# STM32F107VCT7 register map
File version: 1.0
Registers are 32-bit, access not given, reset 0x0 unless marked. A register's access mark holds for its fields unless they carry their own. Offsets are from the block's base; [hi:lo] are bit positions; {n}, {i} and the like mark numbered series.

## FLASH
Base 0x40022000
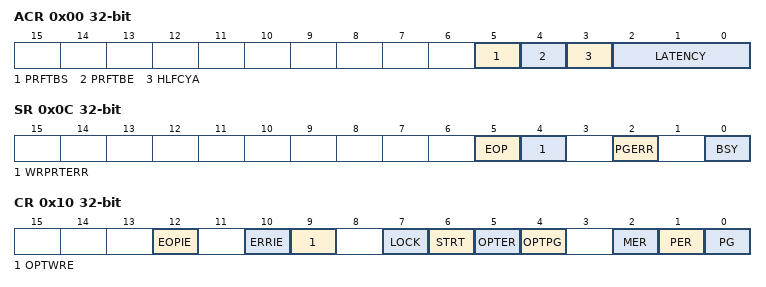
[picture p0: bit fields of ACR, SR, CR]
0x00 ACR
  [5] PRFTBS, [4] PRFTBE, [3] HLFCYA, [2:0] LATENCY
0x04 KEYR
  [31:0] FKEYR
0x08 OPTKEYR
0x0C SR
  [5] EOP, [4] WRPRTERR, [2] PGERR, [0] BSY
0x10 CR
  [12] EOPIE, [10] ERRIE, [9] OPTWRE, [7] LOCK, [6] STRT, [5] OPTER, [4] OPTPG, [2] MER, [1] PER, [0] PG
0x14 AR
  [31:0] FAR
0x1C OBR
  [25:18] DATA1, [17:10] DATA0, [4] nRST_STDBY, [3] nRST_STOP, [4:2] USER, [1] RDPRT, [0] OPTERR
0x20 WRPR
  [31:0] WRP

## CRC
Base 0x40023000
0x00 DR
0x04 IDR 8-bit
0x08 CR
  [0] RESET

## ETH
Base 0x40028000
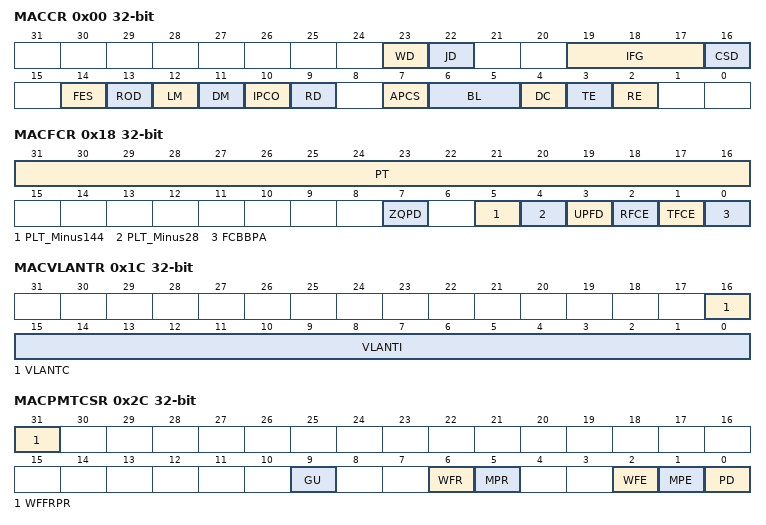
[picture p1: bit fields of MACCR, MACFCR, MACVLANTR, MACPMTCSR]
0x00 MACCR
  [23] WD, [22] JD, [19:17] IFG, [16] CSD, [14] FES, [13] ROD, [12] LM, [11] DM, [10] IPCO, [9] RD, [7] APCS, [6:5] BL, [4] DC, [3] TE, [2] RE
0x04 MACFFR
  [31] RA, [10] HPF, [9] SAF, [8] SAIF, [7] PCF_ForwardAll, [7:6] PCF_ForwardPassedAddrFilter, [5] BFD, [4] PAM, [3] DAIF, [2] HM, [1] HU, [0] PM
0x08 MACHTHR
  [31:0] HTH
0x0C MACHTLR
  [31:0] HTL
0x10 MACMIIAR
  [15:11] PA, [10:6] MR, [3] CR_DIV16, [3:2] CR_DIV26, [1] MW, [0] MB
0x14 MACMIIDR
  [15:0] MD
0x18 MACFCR
  [31:16] PT, [7] ZQPD, [5] PLT_Minus144, [4] PLT_Minus28, [3] UPFD, [2] RFCE, [1] TFCE, [0] FCBBPA
0x1C MACVLANTR
  [16] VLANTC, [15:0] VLANTI
0x28 MACRWUFFR
  [31:0] D
0x2C MACPMTCSR
  [31] WFFRPR, [9] GU, [6] WFR, [5] MPR, [2] WFE, [1] MPE, [0] PD
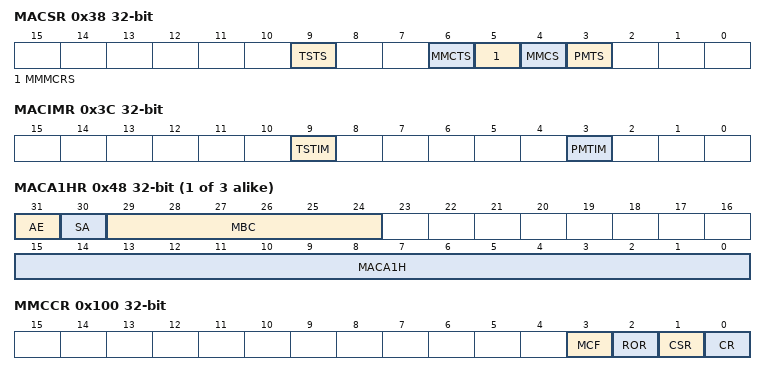
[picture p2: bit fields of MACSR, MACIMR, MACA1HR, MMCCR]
0x38 MACSR
  [9] TSTS, [6] MMCTS, [5] MMMCRS, [4] MMCS, [3] PMTS
0x3C MACIMR
  [9] TSTIM, [3] PMTIM
0x40 MACA0HR
  [15:0] MACA0H
{0x44+8i} MACA{i}LR (i=0..3)
  [31:0] MACA{i}L
{0x40+8i} MACA{i}HR (i=1..3)
  [31] AE, [30] SA, [29:24] MBC, [15:0] MACA{i}H
0x100 MMCCR
  [3] MCF, [2] ROR, [1] CSR, [0] CR
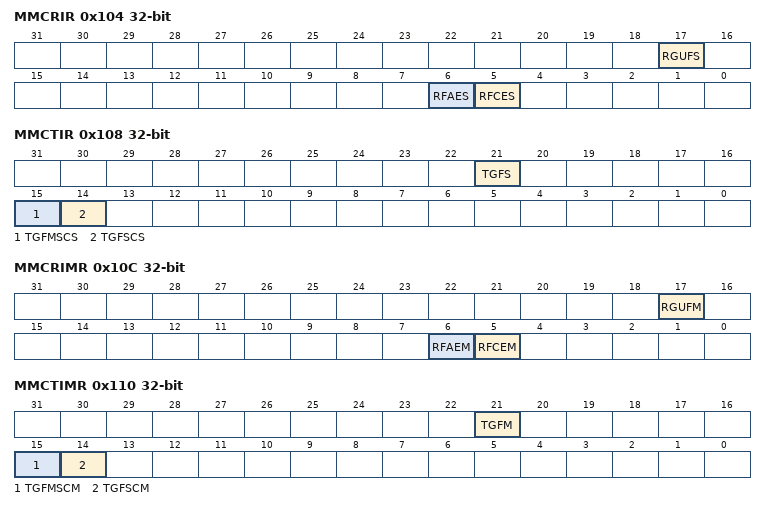
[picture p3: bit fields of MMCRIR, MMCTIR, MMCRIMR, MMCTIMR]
0x104 MMCRIR
  [17] RGUFS, [6] RFAES, [5] RFCES
0x108 MMCTIR
  [21] TGFS, [15] TGFMSCS, [14] TGFSCS
0x10C MMCRIMR
  [17] RGUFM, [6] RFAEM, [5] RFCEM
0x110 MMCTIMR
  [21] TGFM, [15] TGFMSCM, [14] TGFSCM
0x14C MMCTGFSCCR
  [31:0] TGFSCC
0x150 MMCTGFMSCCR
  [31:0] TGFMSCC
0x168 MMCTGFCR
  [31:0] TGFC
0x194 MMCRFCECR
  [31:0] RFCEC
0x198 MMCRFAECR
  [31:0] RFAEC
0x1C4 MMCRGUFCR
  [31:0] RGUFC
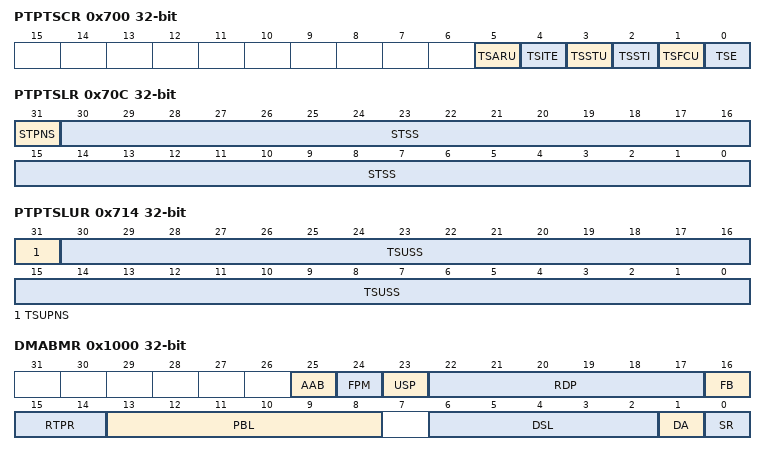
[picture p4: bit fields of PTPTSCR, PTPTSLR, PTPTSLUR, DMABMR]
0x700 PTPTSCR
  [5] TSARU, [4] TSITE, [3] TSSTU, [2] TSSTI, [1] TSFCU, [0] TSE
0x704 PTPSSIR
  [7:0] STSSI
0x708 PTPTSHR
  [31:0] STS
0x70C PTPTSLR
  [31] STPNS, [30:0] STSS
0x710 PTPTSHUR
  [31:0] TSUS
0x714 PTPTSLUR
  [31] TSUPNS, [30:0] TSUSS
0x718 PTPTSAR
  [31:0] TSA
0x71C PTPTTHR
  [31:0] TTSH
0x720 PTPTTLR
  [31:0] TTSL
0x1000 DMABMR
  [25] AAB, [24] FPM, [23] USP, [22:17] RDP, [16] FB, [15:14] RTPR, [13:8] PBL, [6:2] DSL, [1] DA, [0] SR
0x1004 DMATPDR
  [31:0] TPD
0x1008 DMARPDR
  [31:0] RPD
0x100C DMARDLAR
  [31:0] SRL
0x1010 DMATDLAR
  [31:0] STL
0x1014 DMASR
  [29] TSTS, [28] PMTS, [27] MMCS, [25] EBS_DescAccess, [24] EBS_ReadTransf, [23] EBS_DataTransfTx, [21] TPS_Waiting, [21:20] TPS_Reading, [19] RPS_Suspended, [18:17] RPS_Waiting, [16] NIS, [15] AIS, [14] ERS, [13] FBES, [10] ETS, [9] RWTS, [8] RPSS, [7] RBUS, [6] RS, [5] TUS, [4] ROS, [3] TJTS, [2] TBUS, [1] TPSS, [0] TS
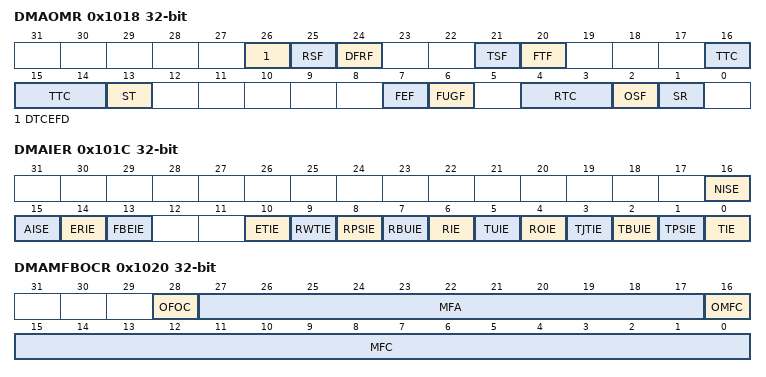
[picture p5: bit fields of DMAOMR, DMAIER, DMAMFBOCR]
0x1018 DMAOMR
  [26] DTCEFD, [25] RSF, [24] DFRF, [21] TSF, [20] FTF, [16:14] TTC, [13] ST, [7] FEF, [6] FUGF, [4:3] RTC, [2] OSF, [1] SR
0x101C DMAIER
  [16] NISE, [15] AISE, [14] ERIE, [13] FBEIE, [10] ETIE, [9] RWTIE, [8] RPSIE, [7] RBUIE, [6] RIE, [5] TUIE, [4] ROIE, [3] TJTIE, [2] TBUIE, [1] TPSIE, [0] TIE
0x1020 DMAMFBOCR
  [28] OFOC, [27:17] MFA, [16] OMFC, [15:0] MFC
0x1048 DMACHTDR
  [31:0] HTDAP
0x104C DMACHRDR
  [31:0] HRDAP
0x1050 DMACHTBAR
  [31:0] HTBAP
0x1054 DMACHRBAR
  [31:0] HRBAP

## USB_OTG_FS
Base 0x50000000
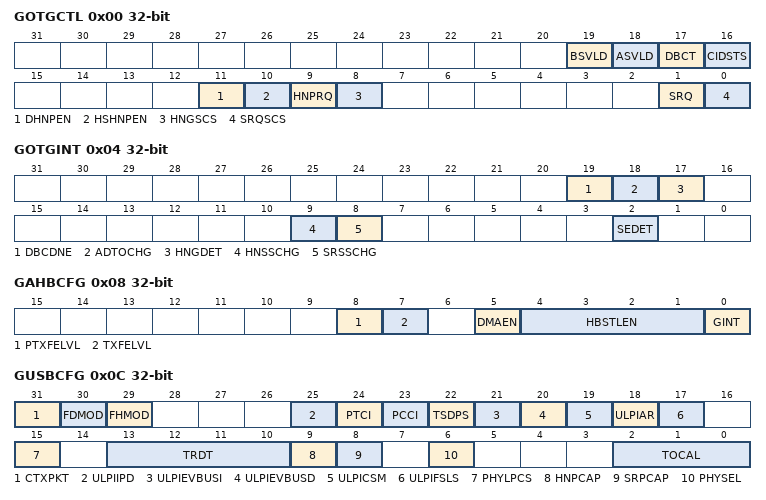
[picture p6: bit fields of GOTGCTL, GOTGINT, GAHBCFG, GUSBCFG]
0x00 GOTGCTL
  [19] BSVLD, [18] ASVLD, [17] DBCT, [16] CIDSTS, [11] DHNPEN, [10] HSHNPEN, [9] HNPRQ, [8] HNGSCS, [1] SRQ, [0] SRQSCS
0x04 GOTGINT
  [19] DBCDNE, [18] ADTOCHG, [17] HNGDET, [9] HNSSCHG, [8] SRSSCHG, [2] SEDET
0x08 GAHBCFG
  [8] PTXFELVL, [7] TXFELVL, [5] DMAEN, [4:1] HBSTLEN, [0] GINT
0x0C GUSBCFG
  [31] CTXPKT, [30] FDMOD, [29] FHMOD, [25] ULPIIPD, [24] PTCI, [23] PCCI, [22] TSDPS, [21] ULPIEVBUSI, [20] ULPIEVBUSD, [19] ULPICSM, [18] ULPIAR, [17] ULPIFSLS, [15] PHYLPCS, [13:10] TRDT, [9] HNPCAP, [8] SRPCAP, [6] PHYSEL, [2:0] TOCAL
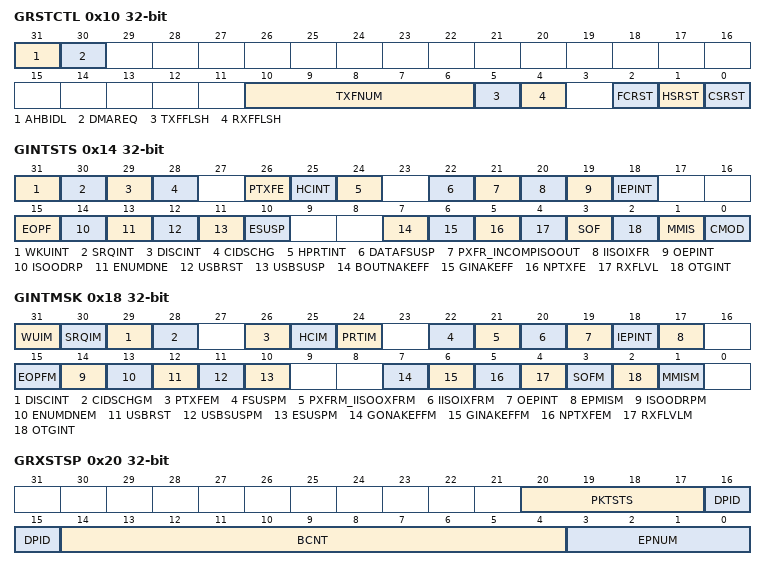
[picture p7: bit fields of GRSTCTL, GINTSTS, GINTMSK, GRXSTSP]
0x10 GRSTCTL
  [31] AHBIDL, [30] DMAREQ, [10:6] TXFNUM, [5] TXFFLSH, [4] RXFFLSH, [2] FCRST, [1] HSRST, [0] CSRST
0x14 GINTSTS
  [31] WKUINT, [30] SRQINT, [29] DISCINT, [28] CIDSCHG, [26] PTXFE, [25] HCINT, [24] HPRTINT, [22] DATAFSUSP, [21] PXFR_INCOMPISOOUT, [20] IISOIXFR, [19] OEPINT, [18] IEPINT, [15] EOPF, [14] ISOODRP, [13] ENUMDNE, [12] USBRST, [11] USBSUSP, [10] ESUSP, [7] BOUTNAKEFF, [6] GINAKEFF, [5] NPTXFE, [4] RXFLVL, [3] SOF, [2] OTGINT, [1] MMIS, [0] CMOD
0x18 GINTMSK
  [31] WUIM, [30] SRQIM, [29] DISCINT, [28] CIDSCHGM, [26] PTXFEM, [25] HCIM, [24] PRTIM, [22] FSUSPM, [21] PXFRM_IISOOXFRM, [20] IISOIXFRM, [19] OEPINT, [18] IEPINT, [17] EPMISM, [15] EOPFM, [14] ISOODRPM, [13] ENUMDNEM, [12] USBRST, [11] USBSUSPM, [10] ESUSPM, [7] GONAKEFFM, [6] GINAKEFFM, [5] NPTXFEM, [4] RXFLVLM, [3] SOFM, [2] OTGINT, [1] MMISM
0x1C GRXSTSR
0x20 GRXSTSP
  [20:17] PKTSTS, [16:15] DPID, [14:4] BCNT, [3:0] EPNUM
0x24 GRXFSIZ
  [15:0] RXFD
0x28 DIEPTXF0_HNPTXFSIZ
0x2C HNPTXSTS
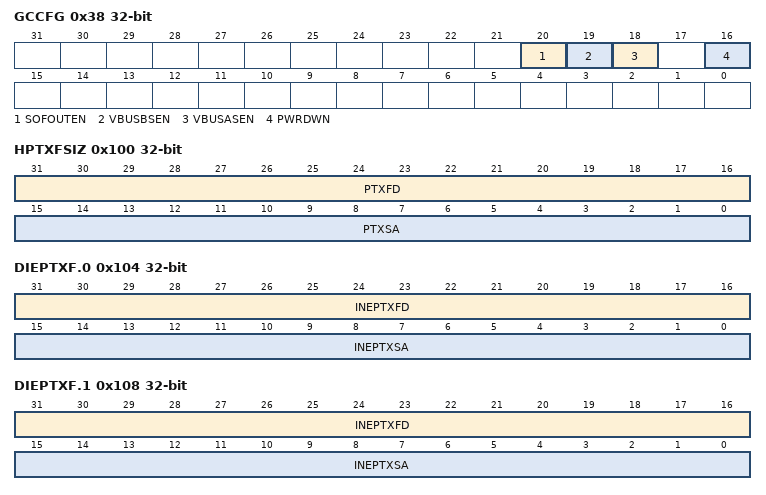
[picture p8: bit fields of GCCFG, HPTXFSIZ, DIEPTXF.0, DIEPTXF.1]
0x38 GCCFG
  [20] SOFOUTEN, [19] VBUSBSEN, [18] VBUSASEN, [16] PWRDWN
0x3C CID
  [31:0] PRODUCT_ID
0x100 HPTXFSIZ
  [31:16] PTXFD, [15:0] PTXSA
0x104 DIEPTXF.0
  [31:16] INEPTXFD, [15:0] INEPTXSA
0x108 DIEPTXF.1
  [31:16] INEPTXFD, [15:0] INEPTXSA
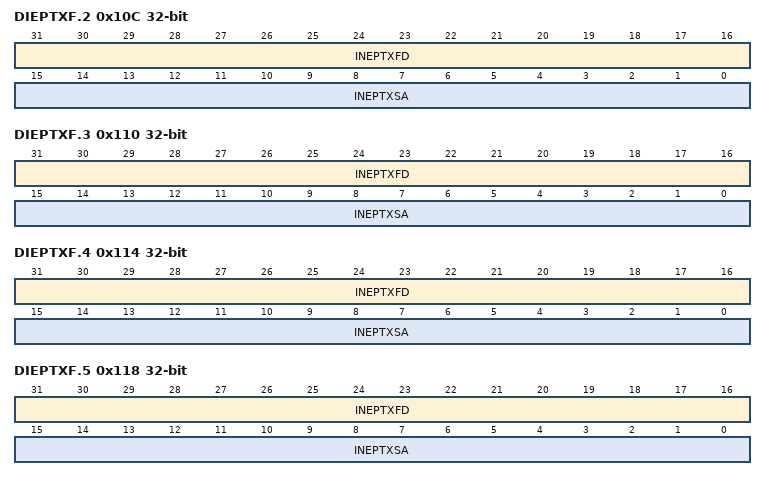
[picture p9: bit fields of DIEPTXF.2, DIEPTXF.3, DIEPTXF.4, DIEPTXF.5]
0x10C DIEPTXF.2
  [31:16] INEPTXFD, [15:0] INEPTXSA
0x110 DIEPTXF.3
  [31:16] INEPTXFD, [15:0] INEPTXSA
0x114 DIEPTXF.4
  [31:16] INEPTXFD, [15:0] INEPTXSA
0x118 DIEPTXF.5
  [31:16] INEPTXFD, [15:0] INEPTXSA
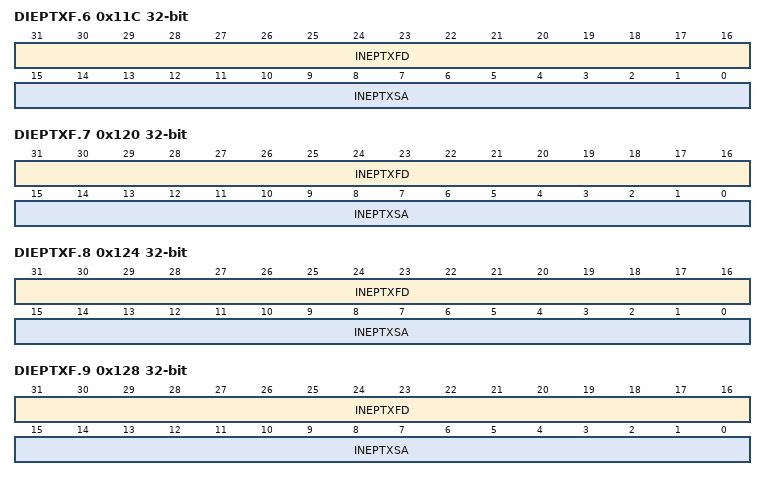
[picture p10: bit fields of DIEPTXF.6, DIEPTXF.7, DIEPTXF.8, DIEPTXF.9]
0x11C DIEPTXF.6
  [31:16] INEPTXFD, [15:0] INEPTXSA
0x120 DIEPTXF.7
  [31:16] INEPTXFD, [15:0] INEPTXSA
0x124 DIEPTXF.8
  [31:16] INEPTXFD, [15:0] INEPTXSA
0x128 DIEPTXF.9
  [31:16] INEPTXFD, [15:0] INEPTXSA
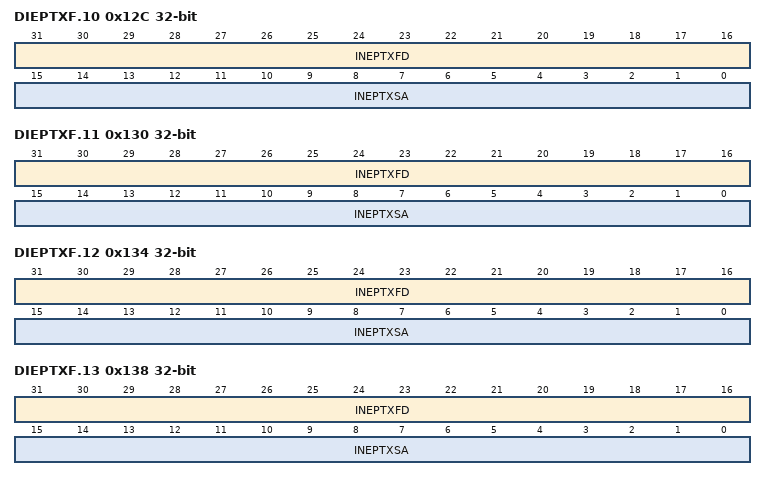
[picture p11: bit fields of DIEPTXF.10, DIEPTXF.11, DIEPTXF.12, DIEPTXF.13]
0x12C DIEPTXF.10
  [31:16] INEPTXFD, [15:0] INEPTXSA
0x130 DIEPTXF.11
  [31:16] INEPTXFD, [15:0] INEPTXSA
0x134 DIEPTXF.12
  [31:16] INEPTXFD, [15:0] INEPTXSA
0x138 DIEPTXF.13
  [31:16] INEPTXFD, [15:0] INEPTXSA
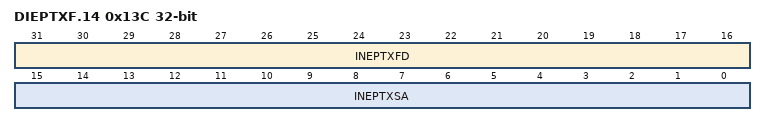
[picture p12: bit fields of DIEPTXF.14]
0x13C DIEPTXF.14
  [31:16] INEPTXFD, [15:0] INEPTXSA

## DBGMCU
Base 0xE0042000
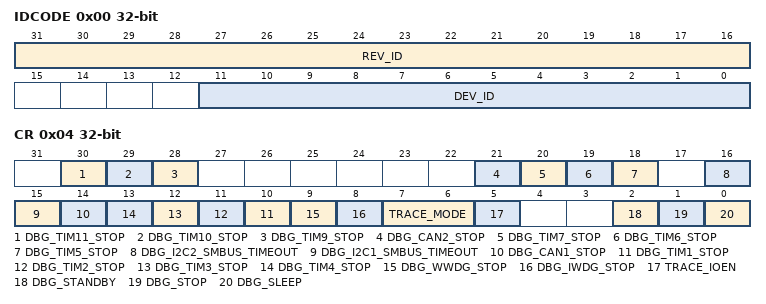
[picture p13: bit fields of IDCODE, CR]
0x00 IDCODE
  [31:16] REV_ID, [11:0] DEV_ID
0x04 CR
  [30] DBG_TIM11_STOP, [29] DBG_TIM10_STOP, [28] DBG_TIM9_STOP, [21] DBG_CAN2_STOP, [20] DBG_TIM7_STOP, [19] DBG_TIM6_STOP, [18] DBG_TIM5_STOP, [16] DBG_I2C2_SMBUS_TIMEOUT, [15] DBG_I2C1_SMBUS_TIMEOUT, [14] DBG_CAN1_STOP, [n+9] DBG_TIM{n}_STOP (n=1..4), [9] DBG_WWDG_STOP, [8] DBG_IWDG_STOP, [7:6] TRACE_MODE, [5] TRACE_IOEN, [2] DBG_STANDBY, [1] DBG_STOP, [0] DBG_SLEEP
